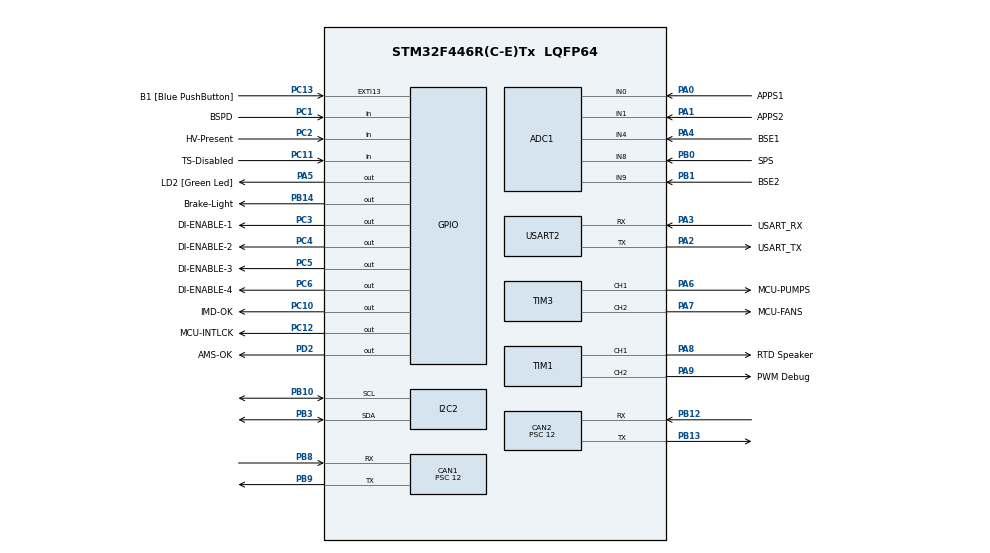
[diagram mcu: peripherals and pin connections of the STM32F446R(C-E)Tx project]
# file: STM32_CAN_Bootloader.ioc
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ADC1.Channel-2\#ChannelRegularConversion=ADC_CHANNEL_1
ADC1.Channel-3\#ChannelRegularConversion=ADC_CHANNEL_4
ADC1.Channel-4\#ChannelRegularConversion=ADC_CHANNEL_9
ADC1.Channel-5\#ChannelRegularConversion=ADC_CHANNEL_8
ADC1.Channel-8\#ChannelRegularConversion=ADC_CHANNEL_VREFINT
ADC1.DMAContinuousRequests=DISABLE
ADC1.EOCSelection=ADC_EOC_SEQ_CONV
ADC1.ExternalTrigConv=ADC_SOFTWARE_START
ADC1.NbrOfConversion=6
ADC1.NbrOfConversionFlag=1
ADC1.Rank-2\#ChannelRegularConversion=2
ADC1.Rank-3\#ChannelRegularConversion=3
ADC1.Rank-4\#ChannelRegularConversion=4
ADC1.Rank-5\#ChannelRegularConversion=5
ADC1.Rank-8\#ChannelRegularConversion=6
ADC1.SamplingTime-1\#ChannelRegularConversion=ADC_SAMPLETIME_56CYCLES
ADC1.SamplingTime-2\#ChannelRegularConversion=ADC_SAMPLETIME_56CYCLES
ADC1.SamplingTime-3\#ChannelRegularConversion=ADC_SAMPLETIME_56CYCLES
ADC1.SamplingTime-4\#ChannelRegularConversion=ADC_SAMPLETIME_56CYCLES
ADC1.SamplingTime-5\#ChannelRegularConversion=ADC_SAMPLETIME_56CYCLES
ADC1.SamplingTime-8\#ChannelRegularConversion=ADC_SAMPLETIME_480CYCLES
ADC1.master=1
CAN1.ABOM=ENABLE
CAN1.AWUM=ENABLE
CAN1.BS1=CAN_BS1_10TQ
CAN1.BS2=CAN_BS2_3TQ
CAN1.CalculateBaudRate=250000
CAN1.CalculateTimeBit=4000
CAN1.CalculateTimeQuantum=285.7142857142857
CAN1.NART=ENABLE
CAN1.Prescaler=12
CAN1.TXFP=ENABLE
CAN2.ABOM=ENABLE
CAN2.AWUM=ENABLE
CAN2.BS1=CAN_BS1_10TQ
CAN2.BS2=CAN_BS2_3TQ
CAN2.CalculateBaudRate=250000
CAN2.CalculateTimeBit=4000
CAN2.CalculateTimeQuantum=285.7142857142857
CAN2.NART=ENABLE
CAN2.Prescaler=12
Dma.ADC1.0.Direction=DMA_PERIPH_TO_MEMORY
Dma.ADC1.0.FIFOMode=DMA_FIFOMODE_DISABLE
Dma.ADC1.0.Instance=DMA2_Stream0
Dma.ADC1.0.MemDataAlignment=DMA_MDATAALIGN_HALFWORD
Dma.ADC1.0.MemInc=DMA_MINC_ENABLE
Dma.ADC1.0.Mode=DMA_CIRCULAR
Dma.ADC1.0.PeriphDataAlignment=DMA_PDATAALIGN_HALFWORD
Dma.ADC1.0.PeriphInc=DMA_PINC_DISABLE
Dma.ADC1.0.Priority=DMA_PRIORITY_LOW
Dma.Request0=ADC1
Dma.Request1=USART2_RX
Dma.USART2_RX.1.Direction=DMA_PERIPH_TO_MEMORY
Dma.USART2_RX.1.FIFOMode=DMA_FIFOMODE_DISABLE
Dma.USART2_RX.1.Instance=DMA1_Stream5
Dma.USART2_RX.1.MemDataAlignment=DMA_MDATAALIGN_BYTE
Dma.USART2_RX.1.MemInc=DMA_MINC_ENABLE
Dma.USART2_RX.1.Mode=DMA_NORMAL
Dma.USART2_RX.1.PeriphDataAlignment=DMA_PDATAALIGN_BYTE
Dma.USART2_RX.1.PeriphInc=DMA_PINC_DISABLE
Dma.USART2_RX.1.Priority=DMA_PRIORITY_LOW
Mcu.Family=STM32F4
Mcu.Name=STM32F446R(C-E)Tx
Mcu.Package=LQFP64
NVIC.CAN1_RX0_IRQn=true\:0\:0\:false\:false\:true\:true\:true\:true
NVIC.CAN1_RX1_IRQn=true\:0\:0\:false\:false\:true\:true\:true\:true
NVIC.CAN1_TX_IRQn=true\:0\:0\:false\:false\:true\:true\:true\:true
NVIC.CAN2_RX0_IRQn=true\:0\:0\:false\:false\:true\:true\:true\:true
NVIC.CAN2_TX_IRQn=true\:0\:0\:false\:false\:true\:true\:true\:true
NVIC.DMA1_Stream5_IRQn=true\:0\:0\:false\:false\:true\:false\:true\:true
NVIC.DMA2_Stream0_IRQn=true\:0\:0\:false\:false\:true\:false\:true\:true
NVIC.PriorityGroup=NVIC_PRIORITYGROUP_4
NVIC.TIM5_IRQn=true\:15\:0\:false\:false\:true\:false\:true\:true
NVIC.TimeBase=TIM5_IRQn
NVIC.TimeBaseIP=TIM5
PA0-WKUP.GPIO_Label=APPS1
PA0-WKUP.GPIO_Mode=GPIO_MODE_ANALOG
PA0-WKUP.GPIO_PuPd=GPIO_NOPULL
PA0-WKUP.Signal=ADCx_IN0
PA1.GPIO_Label=APPS2
PA1.GPIO_Mode=GPIO_MODE_ANALOG
PA1.GPIO_PuPd=GPIO_NOPULL
PA1.Signal=ADCx_IN1
PA13.GPIO_Label=TMS
PA13.Mode=Serial_Wire
PA13.Signal=SYS_JTMS-SWDIO
PA14.GPIO_Label=TCK
PA14.Mode=Serial_Wire
PA14.Signal=SYS_JTCK-SWCLK
PA2.GPIO_Label=USART_TX
PA2.Mode=Asynchronous
PA2.Signal=USART2_TX
PA3.GPIO_Label=USART_RX
PA3.Mode=Asynchronous
PA3.Signal=USART2_RX
PA4.GPIO_Label=BSE1
PA4.Signal=ADCx_IN4
PA5.GPIO_Label=LD2 [Green Led]
PA5.Signal=GPIO_Output
PA6.GPIO_Label=MCU-PUMPS
PA6.Signal=S_TIM3_CH1
PA7.GPIO_Label=MCU-FANS
PA7.Signal=S_TIM3_CH2
PA8.GPIO_Label=RTD Speaker
PA8.Signal=S_TIM1_CH1
PA9.GPIO_Label=PWM Debug
PA9.Signal=S_TIM1_CH2
PB0.GPIO_Label=SPS
PB0.GPIO_Mode=GPIO_MODE_ANALOG
PB0.GPIO_PuPd=GPIO_NOPULL
PB0.Signal=ADCx_IN8
PB1.GPIO_Label=BSE2
PB1.GPIO_Mode=GPIO_MODE_ANALOG
PB1.GPIO_PuPd=GPIO_NOPULL
PB1.Signal=ADCx_IN9
PB10.Mode=I2C
PB10.Signal=I2C2_SCL
PB12.Mode=CAN_Activate
PB12.Signal=CAN2_RX
PB13.Mode=CAN_Activate
PB13.Signal=CAN2_TX
PB14.GPIO_Label=Brake-Light
PB14.Signal=GPIO_Output
PB3.Mode=I2C
PB3.Signal=I2C2_SDA
PB7.Signal=USART1_RX
PB8.Mode=CAN_Activate
PB8.Signal=CAN1_RX
PB9.Mode=CAN_Activate
PB9.Signal=CAN1_TX
PC1.GPIO_Label=BSPD
PC1.Signal=GPIO_Input
PC10.GPIO_Label=IMD-OK
PC10.Signal=GPIO_Output
PC11.GPIO_Label=TS-Disabled
PC11.Signal=GPIO_Input
PC12.GPIO_Label=MCU-INTLCK
PC12.Signal=GPIO_Output
PC13.GPIO_Label=B1 [Blue PushButton]
PC13.GPIO_ModeDefaultEXTI=GPIO_MODE_IT_FALLING
PC13.Signal=GPXTI13
PC14-OSC32_IN.Mode=LSE-External-Oscillator
PC14-OSC32_IN.Signal=RCC_OSC32_IN
PC15-OSC32_OUT.Mode=LSE-External-Oscillator
PC15-OSC32_OUT.Signal=RCC_OSC32_OUT
PC2.GPIO_Label=HV-Present
PC2.Signal=GPIO_Input
PC3.GPIO_Label=DI-ENABLE-1
PC3.GPIO_ModeDefaultOutputPP=GPIO_MODE_OUTPUT_OD
PC3.GPIO_PuPd=GPIO_NOPULL
PC3.PinState=GPIO_PIN_SET
PC3.Signal=GPIO_Output
PC4.GPIO_Label=DI-ENABLE-2
PC4.GPIO_ModeDefaultOutputPP=GPIO_MODE_OUTPUT_OD
PC4.GPIO_PuPd=GPIO_NOPULL
PC4.PinState=GPIO_PIN_SET
PC4.Signal=GPIO_Output
PC5.GPIO_Label=DI-ENABLE-3
PC5.GPIO_ModeDefaultOutputPP=GPIO_MODE_OUTPUT_OD
PC5.GPIO_PuPd=GPIO_NOPULL
PC5.PinState=GPIO_PIN_SET
PC5.Signal=GPIO_Output
PC6.GPIO_Label=DI-ENABLE-4
PC6.GPIO_ModeDefaultOutputPP=GPIO_MODE_OUTPUT_OD
PC6.GPIO_PuPd=GPIO_NOPULL
PC6.PinState=GPIO_PIN_SET
PC6.Signal=GPIO_Output
PD2.GPIO_Label=AMS-OK
PD2.Signal=GPIO_Output
PH0-OSC_IN.Mode=HSE-External-Oscillator
PH0-OSC_IN.Signal=RCC_OSC_IN
PH1-OSC_OUT.Mode=HSE-External-Oscillator
PH1-OSC_OUT.Signal=RCC_OSC_OUT
ProjectManager.HeapSize=0x200
ProjectManager.StackSize=0x400
ProjectManager.TargetToolchain=STM32CubeIDE
RCC.48MHZClocksFreq_Value=84000000
RCC.AHBFreq_Value=84000000
RCC.APB1CLKDivider=RCC_HCLK_DIV2
RCC.APB1Freq_Value=42000000
RCC.APB1TimFreq_Value=84000000
RCC.APB2Freq_Value=84000000
RCC.APB2TimFreq_Value=84000000
RCC.CortexFreq_Value=84000000
RCC.FLatency-AdvancedSettings=FLASH_LATENCY_2
RCC.HCLKFreq_Value=84000000
RCC.HSE_VALUE=8000000
RCC.HSI_VALUE=16000000
RCC.PLLN=336
RCC.PLLP=RCC_PLLP_DIV4
RCC.SYSCLKFreq_VALUE=84000000
RCC.SYSCLKSource=RCC_SYSCLKSOURCE_PLLCLK
RCC.USBFreq_Value=168000000
RCC.VCOOutputFreq_Value=336000000
SH.ADCx_IN0.0=ADC1_IN0,IN0
SH.ADCx_IN1.0=ADC1_IN1,IN1
SH.ADCx_IN4.0=ADC1_IN4,IN4
SH.ADCx_IN8.0=ADC1_IN8,IN8
SH.ADCx_IN9.0=ADC1_IN9,IN9
SH.S_TIM1_CH1.0=TIM1_CH1,PWM Generation1 CH1
SH.S_TIM1_CH2.0=TIM1_CH2,PWM Generation2 CH2
SH.S_TIM3_CH1.0=TIM3_CH1,PWM Generation1 CH1
SH.S_TIM3_CH2.0=TIM3_CH2,PWM Generation2 CH2
TIM1.Channel-PWM\ Generation1\ CH1=TIM_CHANNEL_1
TIM1.Channel-PWM\ Generation2\ CH2=TIM_CHANNEL_2
TIM3.Channel-PWM\ Generation1\ CH1=TIM_CHANNEL_1
TIM3.Channel-PWM\ Generation2\ CH2=TIM_CHANNEL_2
USART2.VirtualMode=VM_ASYNC
VP_ADC1_Vref_Input.Mode=IN-Vrefint
VP_SYS_VS_tim5.Mode=TIM5
VP_TIM1_VS_ClockSourceINT.Mode=Internal
VP_TIM3_VS_ClockSourceINT.Mode=Internal
board=NUCLEO-F446RE

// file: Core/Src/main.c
/* USER CODE BEGIN Header */
/**
  ******************************************************************************
  * @file           : main.c
  * @brief          : Main program body
  ******************************************************************************
  * @attention
  *
  * Copyright (c) 2026 STMicroelectronics.
  * All rights reserved.
  *
  * This software is licensed under terms that can be found in the LICENSE file
  * in the root directory of this software component.
  * If no LICENSE file comes with this software, it is provided AS-IS.
  *
  ******************************************************************************
  */
/* USER CODE END Header */
#include "main.h"

/* USER CODE BEGIN Includes */
#include "bootloader.h"
/* USER CODE END Includes */

CAN_HandleTypeDef hcan1;
CAN_HandleTypeDef hcan2;

I2C_HandleTypeDef hi2c2;

void SystemClock_Config(void);

int main(void)
{

  /* MCU Configuration--------------------------------------------------------*/

  /* Reset of all peripherals, Initializes the Flash interface and the Systick. */
  HAL_Init();

  /* Configure the system clock */
  SystemClock_Config();

  /* Initialize all configured peripherals */
  MX_GPIO_Init();
  MX_DMA_Init();
  MX_ADC1_Init();
  MX_CAN1_Init();
  MX_CAN2_Init();
  MX_TIM1_Init();
  MX_TIM3_Init();
  MX_USART2_UART_Init();
  MX_I2C2_Init();
  /* USER CODE BEGIN 2 */
  BL_Run(&hcan1);   /* never returns — either flashes then jumps, or jumps directly */
  /* USER CODE END 2 */

  /* Infinite loop */
  while (1)
  {

  }
}

void SystemClock_Config(void)
{
  LL_FLASH_SetLatency(LL_FLASH_LATENCY_2);
  while(LL_FLASH_GetLatency()!= LL_FLASH_LATENCY_2)
  {
  }
  LL_PWR_SetRegulVoltageScaling(LL_PWR_REGU_VOLTAGE_SCALE3);
  LL_PWR_DisableOverDriveMode();
  LL_RCC_HSI_SetCalibTrimming(16);
  LL_RCC_HSI_Enable();

   /* Wait till HSI is ready */
  while(LL_RCC_HSI_IsReady() != 1)
  {

  }
  LL_RCC_PLL_ConfigDomain_SYS(LL_RCC_PLLSOURCE_HSI, LL_RCC_PLLM_DIV_16, 336, LL_RCC_PLLP_DIV_4);
  LL_RCC_PLL_Enable();

   /* Wait till PLL is ready */
  while(LL_RCC_PLL_IsReady() != 1)
  {

  }
  while (LL_PWR_IsActiveFlag_VOS() == 0)
  {
  }
  LL_RCC_SetAHBPrescaler(LL_RCC_SYSCLK_DIV_1);
  LL_RCC_SetAPB1Prescaler(LL_RCC_APB1_DIV_2);
  LL_RCC_SetAPB2Prescaler(LL_RCC_APB2_DIV_1);
  LL_RCC_SetSysClkSource(LL_RCC_SYS_CLKSOURCE_PLL);

   /* Wait till System clock is ready */
  while(LL_RCC_GetSysClkSource() != LL_RCC_SYS_CLKSOURCE_STATUS_PLL)
  {

  }
  LL_SetSystemCoreClock(84000000);

   /* Update the time base */
  if (HAL_InitTick (TICK_INT_PRIORITY) != HAL_OK)
  {
    Error_Handler();
  }
  LL_RCC_SetTIMPrescaler(LL_RCC_TIM_PRESCALER_TWICE);
}

void MX_ADC1_Init(void)
{

  LL_ADC_InitTypeDef ADC_InitStruct = {0};
  LL_ADC_REG_InitTypeDef ADC_REG_InitStruct = {0};
  LL_ADC_CommonInitTypeDef ADC_CommonInitStruct = {0};

  LL_GPIO_InitTypeDef GPIO_InitStruct = {0};

  /* Peripheral clock enable */
  LL_APB2_GRP1_EnableClock(LL_APB2_GRP1_PERIPH_ADC1);

  LL_AHB1_GRP1_EnableClock(LL_AHB1_GRP1_PERIPH_GPIOA);
  LL_AHB1_GRP1_EnableClock(LL_AHB1_GRP1_PERIPH_GPIOB);
  /**ADC1 GPIO Configuration
  PA0-WKUP   ------> ADC1_IN0
  PA1   ------> ADC1_IN1
  PA4   ------> ADC1_IN4
  PB0   ------> ADC1_IN8
  PB1   ------> ADC1_IN9
  */
  GPIO_InitStruct.Pin = APPS1_Pin|APPS2_Pin|BSE1_Pin;
  GPIO_InitStruct.Mode = LL_GPIO_MODE_ANALOG;
  GPIO_InitStruct.Pull = LL_GPIO_PULL_NO;
  LL_GPIO_Init(GPIOA, &GPIO_InitStruct);

  GPIO_InitStruct.Pin = SPS_Pin|BSE2_Pin;
  GPIO_InitStruct.Mode = LL_GPIO_MODE_ANALOG;
  GPIO_InitStruct.Pull = LL_GPIO_PULL_NO;
  LL_GPIO_Init(GPIOB, &GPIO_InitStruct);

  /* ADC1 DMA Init */

  /* ADC1 Init */
  LL_DMA_SetChannelSelection(DMA2, LL_DMA_STREAM_0, LL_DMA_CHANNEL_0);

  LL_DMA_SetDataTransferDirection(DMA2, LL_DMA_STREAM_0, LL_DMA_DIRECTION_PERIPH_TO_MEMORY);

  LL_DMA_SetStreamPriorityLevel(DMA2, LL_DMA_STREAM_0, LL_DMA_PRIORITY_LOW);

  LL_DMA_SetMode(DMA2, LL_DMA_STREAM_0, LL_DMA_MODE_CIRCULAR);

  LL_DMA_SetPeriphIncMode(DMA2, LL_DMA_STREAM_0, LL_DMA_PERIPH_NOINCREMENT);

  LL_DMA_SetMemoryIncMode(DMA2, LL_DMA_STREAM_0, LL_DMA_MEMORY_INCREMENT);

  LL_DMA_SetPeriphSize(DMA2, LL_DMA_STREAM_0, LL_DMA_PDATAALIGN_HALFWORD);

  LL_DMA_SetMemorySize(DMA2, LL_DMA_STREAM_0, LL_DMA_MDATAALIGN_HALFWORD);

  LL_DMA_DisableFifoMode(DMA2, LL_DMA_STREAM_0);

  /** Common config
  */
  ADC_InitStruct.Resolution = LL_ADC_RESOLUTION_12B;
  ADC_InitStruct.DataAlignment = LL_ADC_DATA_ALIGN_RIGHT;
  ADC_InitStruct.SequencersScanMode = LL_ADC_SEQ_SCAN_ENABLE;
  LL_ADC_Init(ADC1, &ADC_InitStruct);
  ADC_REG_InitStruct.TriggerSource = LL_ADC_REG_TRIG_SOFTWARE;
  ADC_REG_InitStruct.SequencerLength = LL_ADC_REG_SEQ_SCAN_ENABLE_6RANKS;
  ADC_REG_InitStruct.SequencerDiscont = LL_ADC_REG_SEQ_DISCONT_DISABLE;
  ADC_REG_InitStruct.ContinuousMode = LL_ADC_REG_CONV_SINGLE;
  ADC_REG_InitStruct.DMATransfer = LL_ADC_REG_DMA_TRANSFER_LIMITED;
  LL_ADC_REG_Init(ADC1, &ADC_REG_InitStruct);
  LL_ADC_REG_SetFlagEndOfConversion(ADC1, LL_ADC_REG_FLAG_EOC_SEQUENCE_CONV);
  ADC_CommonInitStruct.CommonClock = LL_ADC_CLOCK_SYNC_PCLK_DIV4;
  ADC_CommonInitStruct.Multimode = LL_ADC_MULTI_INDEPENDENT;
  LL_ADC_CommonInit(__LL_ADC_COMMON_INSTANCE(ADC1), &ADC_CommonInitStruct);

  /** Configure Regular Channel
  */
  LL_ADC_REG_SetSequencerRanks(ADC1, LL_ADC_REG_RANK_2, LL_ADC_CHANNEL_1);
  LL_ADC_SetChannelSamplingTime(ADC1, LL_ADC_CHANNEL_1, LL_ADC_SAMPLINGTIME_56CYCLES);

  /** Configure Regular Channel
  */
  LL_ADC_REG_SetSequencerRanks(ADC1, LL_ADC_REG_RANK_3, LL_ADC_CHANNEL_4);
  LL_ADC_SetChannelSamplingTime(ADC1, LL_ADC_CHANNEL_4, LL_ADC_SAMPLINGTIME_56CYCLES);

  /** Configure Regular Channel
  */
  LL_ADC_REG_SetSequencerRanks(ADC1, LL_ADC_REG_RANK_4, LL_ADC_CHANNEL_9);
  LL_ADC_SetChannelSamplingTime(ADC1, LL_ADC_CHANNEL_9, LL_ADC_SAMPLINGTIME_56CYCLES);

  /** Configure Regular Channel
  */
  LL_ADC_REG_SetSequencerRanks(ADC1, LL_ADC_REG_RANK_5, LL_ADC_CHANNEL_8);
  LL_ADC_SetChannelSamplingTime(ADC1, LL_ADC_CHANNEL_8, LL_ADC_SAMPLINGTIME_56CYCLES);

  /** Configure Regular Channel
  */
  LL_ADC_REG_SetSequencerRanks(ADC1, LL_ADC_REG_RANK_1, LL_ADC_CHANNEL_0);
  LL_ADC_SetChannelSamplingTime(ADC1, LL_ADC_CHANNEL_0, LL_ADC_SAMPLINGTIME_56CYCLES);

  /** Configure Regular Channel
  */
  LL_ADC_REG_SetSequencerRanks(ADC1, LL_ADC_REG_RANK_6, LL_ADC_CHANNEL_VREFINT);
  LL_ADC_SetChannelSamplingTime(ADC1, LL_ADC_CHANNEL_VREFINT, LL_ADC_SAMPLINGTIME_480CYCLES);
  LL_ADC_SetCommonPathInternalCh(__LL_ADC_COMMON_INSTANCE(ADC1), LL_ADC_PATH_INTERNAL_VREFINT);

}

void MX_CAN1_Init(void)
{

  hcan1.Instance = CAN1;
  hcan1.Init.Prescaler = 12;
  hcan1.Init.Mode = CAN_MODE_NORMAL;
  hcan1.Init.SyncJumpWidth = CAN_SJW_1TQ;
  hcan1.Init.TimeSeg1 = CAN_BS1_10TQ;
  hcan1.Init.TimeSeg2 = CAN_BS2_3TQ;
  hcan1.Init.TimeTriggeredMode = DISABLE;
  hcan1.Init.AutoBusOff = ENABLE;
  hcan1.Init.AutoWakeUp = ENABLE;
  hcan1.Init.AutoRetransmission = ENABLE;
  hcan1.Init.ReceiveFifoLocked = DISABLE;
  hcan1.Init.TransmitFifoPriority = ENABLE;
  if (HAL_CAN_Init(&hcan1) != HAL_OK)
  {
    Error_Handler();
  }

}

void MX_CAN2_Init(void)
{

  hcan2.Instance = CAN2;
  hcan2.Init.Prescaler = 12;
  hcan2.Init.Mode = CAN_MODE_NORMAL;
  hcan2.Init.SyncJumpWidth = CAN_SJW_1TQ;
  hcan2.Init.TimeSeg1 = CAN_BS1_10TQ;
  hcan2.Init.TimeSeg2 = CAN_BS2_3TQ;
  hcan2.Init.TimeTriggeredMode = DISABLE;
  hcan2.Init.AutoBusOff = ENABLE;
  hcan2.Init.AutoWakeUp = ENABLE;
  hcan2.Init.AutoRetransmission = ENABLE;
  hcan2.Init.ReceiveFifoLocked = DISABLE;
  hcan2.Init.TransmitFifoPriority = DISABLE;
  if (HAL_CAN_Init(&hcan2) != HAL_OK)
  {
    Error_Handler();
  }

}

void MX_I2C2_Init(void)
{

  hi2c2.Instance = I2C2;
  hi2c2.Init.ClockSpeed = 100000;
  hi2c2.Init.DutyCycle = I2C_DUTYCYCLE_2;
  hi2c2.Init.OwnAddress1 = 0;
  hi2c2.Init.AddressingMode = I2C_ADDRESSINGMODE_7BIT;
  hi2c2.Init.DualAddressMode = I2C_DUALADDRESS_DISABLE;
  hi2c2.Init.OwnAddress2 = 0;
  hi2c2.Init.GeneralCallMode = I2C_GENERALCALL_DISABLE;
  hi2c2.Init.NoStretchMode = I2C_NOSTRETCH_DISABLE;
  if (HAL_I2C_Init(&hi2c2) != HAL_OK)
  {
    Error_Handler();
  }

}

void MX_TIM1_Init(void)
{

  LL_TIM_InitTypeDef TIM_InitStruct = {0};
  LL_TIM_OC_InitTypeDef TIM_OC_InitStruct = {0};
  LL_TIM_BDTR_InitTypeDef TIM_BDTRInitStruct = {0};

  LL_GPIO_InitTypeDef GPIO_InitStruct = {0};

  /* Peripheral clock enable */
  LL_APB2_GRP1_EnableClock(LL_APB2_GRP1_PERIPH_TIM1);

  TIM_InitStruct.Prescaler = 0;
  TIM_InitStruct.CounterMode = LL_TIM_COUNTERMODE_UP;
  TIM_InitStruct.Autoreload = 65535;
  TIM_InitStruct.ClockDivision = LL_TIM_CLOCKDIVISION_DIV1;
  TIM_InitStruct.RepetitionCounter = 0;
  LL_TIM_Init(TIM1, &TIM_InitStruct);
  LL_TIM_DisableARRPreload(TIM1);
  LL_TIM_SetClockSource(TIM1, LL_TIM_CLOCKSOURCE_INTERNAL);
  LL_TIM_OC_EnablePreload(TIM1, LL_TIM_CHANNEL_CH1);
  TIM_OC_InitStruct.OCMode = LL_TIM_OCMODE_PWM1;
  TIM_OC_InitStruct.OCState = LL_TIM_OCSTATE_DISABLE;
  TIM_OC_InitStruct.OCNState = LL_TIM_OCSTATE_DISABLE;
  TIM_OC_InitStruct.CompareValue = 0;
  TIM_OC_InitStruct.OCPolarity = LL_TIM_OCPOLARITY_HIGH;
  TIM_OC_InitStruct.OCNPolarity = LL_TIM_OCPOLARITY_HIGH;
  TIM_OC_InitStruct.OCIdleState = LL_TIM_OCIDLESTATE_LOW;
  TIM_OC_InitStruct.OCNIdleState = LL_TIM_OCIDLESTATE_LOW;
  LL_TIM_OC_Init(TIM1, LL_TIM_CHANNEL_CH1, &TIM_OC_InitStruct);
  LL_TIM_OC_DisableFast(TIM1, LL_TIM_CHANNEL_CH1);
  LL_TIM_OC_EnablePreload(TIM1, LL_TIM_CHANNEL_CH2);
  LL_TIM_OC_Init(TIM1, LL_TIM_CHANNEL_CH2, &TIM_OC_InitStruct);
  LL_TIM_OC_DisableFast(TIM1, LL_TIM_CHANNEL_CH2);
  LL_TIM_SetTriggerOutput(TIM1, LL_TIM_TRGO_RESET);
  LL_TIM_DisableMasterSlaveMode(TIM1);
  TIM_BDTRInitStruct.OSSRState = LL_TIM_OSSR_DISABLE;
  TIM_BDTRInitStruct.OSSIState = LL_TIM_OSSI_DISABLE;
  TIM_BDTRInitStruct.LockLevel = LL_TIM_LOCKLEVEL_OFF;
  TIM_BDTRInitStruct.DeadTime = 0;
  TIM_BDTRInitStruct.BreakState = LL_TIM_BREAK_DISABLE;
  TIM_BDTRInitStruct.BreakPolarity = LL_TIM_BREAK_POLARITY_HIGH;
  TIM_BDTRInitStruct.AutomaticOutput = LL_TIM_AUTOMATICOUTPUT_DISABLE;
  LL_TIM_BDTR_Init(TIM1, &TIM_BDTRInitStruct);
  LL_AHB1_GRP1_EnableClock(LL_AHB1_GRP1_PERIPH_GPIOA);
  /**TIM1 GPIO Configuration
  PA8   ------> TIM1_CH1
  PA9   ------> TIM1_CH2
  */
  GPIO_InitStruct.Pin = RTD_Speaker_Pin|PWM_Debug_Pin;
  GPIO_InitStruct.Mode = LL_GPIO_MODE_ALTERNATE;
  GPIO_InitStruct.Speed = LL_GPIO_SPEED_FREQ_LOW;
  GPIO_InitStruct.OutputType = LL_GPIO_OUTPUT_PUSHPULL;
  GPIO_InitStruct.Pull = LL_GPIO_PULL_NO;
  GPIO_InitStruct.Alternate = LL_GPIO_AF_1;
  LL_GPIO_Init(GPIOA, &GPIO_InitStruct);

}

void MX_TIM3_Init(void)
{

  LL_TIM_InitTypeDef TIM_InitStruct = {0};
  LL_TIM_OC_InitTypeDef TIM_OC_InitStruct = {0};

  LL_GPIO_InitTypeDef GPIO_InitStruct = {0};

  /* Peripheral clock enable */
  LL_APB1_GRP1_EnableClock(LL_APB1_GRP1_PERIPH_TIM3);

  TIM_InitStruct.Prescaler = 0;
  TIM_InitStruct.CounterMode = LL_TIM_COUNTERMODE_UP;
  TIM_InitStruct.Autoreload = 65535;
  TIM_InitStruct.ClockDivision = LL_TIM_CLOCKDIVISION_DIV1;
  LL_TIM_Init(TIM3, &TIM_InitStruct);
  LL_TIM_DisableARRPreload(TIM3);
  LL_TIM_SetClockSource(TIM3, LL_TIM_CLOCKSOURCE_INTERNAL);
  LL_TIM_OC_EnablePreload(TIM3, LL_TIM_CHANNEL_CH1);
  TIM_OC_InitStruct.OCMode = LL_TIM_OCMODE_PWM1;
  TIM_OC_InitStruct.OCState = LL_TIM_OCSTATE_DISABLE;
  TIM_OC_InitStruct.OCNState = LL_TIM_OCSTATE_DISABLE;
  TIM_OC_InitStruct.CompareValue = 0;
  TIM_OC_InitStruct.OCPolarity = LL_TIM_OCPOLARITY_HIGH;
  LL_TIM_OC_Init(TIM3, LL_TIM_CHANNEL_CH1, &TIM_OC_InitStruct);
  LL_TIM_OC_DisableFast(TIM3, LL_TIM_CHANNEL_CH1);
  LL_TIM_OC_EnablePreload(TIM3, LL_TIM_CHANNEL_CH2);
  LL_TIM_OC_Init(TIM3, LL_TIM_CHANNEL_CH2, &TIM_OC_InitStruct);
  LL_TIM_OC_DisableFast(TIM3, LL_TIM_CHANNEL_CH2);
  LL_TIM_SetTriggerOutput(TIM3, LL_TIM_TRGO_RESET);
  LL_TIM_DisableMasterSlaveMode(TIM3);
  LL_AHB1_GRP1_EnableClock(LL_AHB1_GRP1_PERIPH_GPIOA);
  /**TIM3 GPIO Configuration
  PA6   ------> TIM3_CH1
  PA7   ------> TIM3_CH2
  */
  GPIO_InitStruct.Pin = MCU_PUMPS_Pin|MCU_FANS_Pin;
  GPIO_InitStruct.Mode = LL_GPIO_MODE_ALTERNATE;
  GPIO_InitStruct.Speed = LL_GPIO_SPEED_FREQ_LOW;
  GPIO_InitStruct.OutputType = LL_GPIO_OUTPUT_PUSHPULL;
  GPIO_InitStruct.Pull = LL_GPIO_PULL_NO;
  GPIO_InitStruct.Alternate = LL_GPIO_AF_2;
  LL_GPIO_Init(GPIOA, &GPIO_InitStruct);

}

void MX_USART2_UART_Init(void)
{

  LL_USART_InitTypeDef USART_InitStruct = {0};

  LL_GPIO_InitTypeDef GPIO_InitStruct = {0};

  /* Peripheral clock enable */
  LL_APB1_GRP1_EnableClock(LL_APB1_GRP1_PERIPH_USART2);

  LL_AHB1_GRP1_EnableClock(LL_AHB1_GRP1_PERIPH_GPIOA);
  /**USART2 GPIO Configuration
  PA2   ------> USART2_TX
  PA3   ------> USART2_RX
  */
  GPIO_InitStruct.Pin = USART_TX_Pin|USART_RX_Pin;
  GPIO_InitStruct.Mode = LL_GPIO_MODE_ALTERNATE;
  GPIO_InitStruct.Speed = LL_GPIO_SPEED_FREQ_VERY_HIGH;
  GPIO_InitStruct.OutputType = LL_GPIO_OUTPUT_PUSHPULL;
  GPIO_InitStruct.Pull = LL_GPIO_PULL_NO;
  GPIO_InitStruct.Alternate = LL_GPIO_AF_7;
  LL_GPIO_Init(GPIOA, &GPIO_InitStruct);

  /* USART2 DMA Init */

  /* USART2_RX Init */
  LL_DMA_SetChannelSelection(DMA1, LL_DMA_STREAM_5, LL_DMA_CHANNEL_4);

  LL_DMA_SetDataTransferDirection(DMA1, LL_DMA_STREAM_5, LL_DMA_DIRECTION_PERIPH_TO_MEMORY);

  LL_DMA_SetStreamPriorityLevel(DMA1, LL_DMA_STREAM_5, LL_DMA_PRIORITY_LOW);

  LL_DMA_SetMode(DMA1, LL_DMA_STREAM_5, LL_DMA_MODE_NORMAL);

  LL_DMA_SetPeriphIncMode(DMA1, LL_DMA_STREAM_5, LL_DMA_PERIPH_NOINCREMENT);

  LL_DMA_SetMemoryIncMode(DMA1, LL_DMA_STREAM_5, LL_DMA_MEMORY_INCREMENT);

  LL_DMA_SetPeriphSize(DMA1, LL_DMA_STREAM_5, LL_DMA_PDATAALIGN_BYTE);

  LL_DMA_SetMemorySize(DMA1, LL_DMA_STREAM_5, LL_DMA_MDATAALIGN_BYTE);

  LL_DMA_DisableFifoMode(DMA1, LL_DMA_STREAM_5);

  USART_InitStruct.BaudRate = 115200;
  USART_InitStruct.DataWidth = LL_USART_DATAWIDTH_8B;
  USART_InitStruct.StopBits = LL_USART_STOPBITS_1;
  USART_InitStruct.Parity = LL_USART_PARITY_NONE;
  USART_InitStruct.TransferDirection = LL_USART_DIRECTION_TX_RX;
  USART_InitStruct.HardwareFlowControl = LL_USART_HWCONTROL_NONE;
  USART_InitStruct.OverSampling = LL_USART_OVERSAMPLING_16;
  LL_USART_Init(USART2, &USART_InitStruct);
  LL_USART_ConfigAsyncMode(USART2);
  LL_USART_Enable(USART2);

}

void MX_DMA_Init(void)
{

  /* Init with LL driver */
  /* DMA controller clock enable */
  LL_AHB1_GRP1_EnableClock(LL_AHB1_GRP1_PERIPH_DMA2);
  LL_AHB1_GRP1_EnableClock(LL_AHB1_GRP1_PERIPH_DMA1);

  /* DMA interrupt init */
  /* DMA1_Stream5_IRQn interrupt configuration */
  NVIC_SetPriority(DMA1_Stream5_IRQn, NVIC_EncodePriority(NVIC_GetPriorityGrouping(),0, 0));
  NVIC_EnableIRQ(DMA1_Stream5_IRQn);
  /* DMA2_Stream0_IRQn interrupt configuration */
  NVIC_SetPriority(DMA2_Stream0_IRQn, NVIC_EncodePriority(NVIC_GetPriorityGrouping(),0, 0));
  NVIC_EnableIRQ(DMA2_Stream0_IRQn);

}

void MX_GPIO_Init(void)
{
  LL_EXTI_InitTypeDef EXTI_InitStruct = {0};
  LL_GPIO_InitTypeDef GPIO_InitStruct = {0};

  /* GPIO Ports Clock Enable */
  LL_AHB1_GRP1_EnableClock(LL_AHB1_GRP1_PERIPH_GPIOC);
  LL_AHB1_GRP1_EnableClock(LL_AHB1_GRP1_PERIPH_GPIOH);
  LL_AHB1_GRP1_EnableClock(LL_AHB1_GRP1_PERIPH_GPIOA);
  LL_AHB1_GRP1_EnableClock(LL_AHB1_GRP1_PERIPH_GPIOB);
  LL_AHB1_GRP1_EnableClock(LL_AHB1_GRP1_PERIPH_GPIOD);

  /**/
  LL_GPIO_SetOutputPin(GPIOC, DI_ENABLE_1_Pin|DI_ENABLE_2_Pin|DI_ENABLE_3_Pin|DI_ENABLE_4_Pin);

  /**/
  LL_GPIO_ResetOutputPin(LD2_GPIO_Port, LD2_Pin);

  /**/
  LL_GPIO_ResetOutputPin(Brake_Light_GPIO_Port, Brake_Light_Pin);

  /**/
  LL_GPIO_ResetOutputPin(GPIOC, IMD_OK_Pin|MCU_INTLCK_Pin);

  /**/
  LL_GPIO_ResetOutputPin(AMS_OK_GPIO_Port, AMS_OK_Pin);

  /**/
  LL_SYSCFG_SetEXTISource(LL_SYSCFG_EXTI_PORTC, LL_SYSCFG_EXTI_LINE13);

  /**/
  EXTI_InitStruct.Line_0_31 = LL_EXTI_LINE_13;
  EXTI_InitStruct.LineCommand = ENABLE;
  EXTI_InitStruct.Mode = LL_EXTI_MODE_IT;
  EXTI_InitStruct.Trigger = LL_EXTI_TRIGGER_FALLING;
  LL_EXTI_Init(&EXTI_InitStruct);

  /**/
  LL_GPIO_SetPinPull(B1_GPIO_Port, B1_Pin, LL_GPIO_PULL_NO);

  /**/
  LL_GPIO_SetPinMode(B1_GPIO_Port, B1_Pin, LL_GPIO_MODE_INPUT);

  /**/
  GPIO_InitStruct.Pin = BSPD_Pin|HV_Present_Pin|TS_Disabled_Pin;
  GPIO_InitStruct.Mode = LL_GPIO_MODE_INPUT;
  GPIO_InitStruct.Pull = LL_GPIO_PULL_NO;
  LL_GPIO_Init(GPIOC, &GPIO_InitStruct);

  /**/
  GPIO_InitStruct.Pin = DI_ENABLE_1_Pin|DI_ENABLE_2_Pin|DI_ENABLE_3_Pin|DI_ENABLE_4_Pin;
  GPIO_InitStruct.Mode = LL_GPIO_MODE_OUTPUT;
  GPIO_InitStruct.Speed = LL_GPIO_SPEED_FREQ_LOW;
  GPIO_InitStruct.OutputType = LL_GPIO_OUTPUT_OPENDRAIN;
  GPIO_InitStruct.Pull = LL_GPIO_PULL_NO;
  LL_GPIO_Init(GPIOC, &GPIO_InitStruct);

  /**/
  GPIO_InitStruct.Pin = LD2_Pin;
  GPIO_InitStruct.Mode = LL_GPIO_MODE_OUTPUT;
  GPIO_InitStruct.Speed = LL_GPIO_SPEED_FREQ_LOW;
  GPIO_InitStruct.OutputType = LL_GPIO_OUTPUT_PUSHPULL;
  GPIO_InitStruct.Pull = LL_GPIO_PULL_NO;
  LL_GPIO_Init(LD2_GPIO_Port, &GPIO_InitStruct);

  /**/
  GPIO_InitStruct.Pin = Brake_Light_Pin;
  GPIO_InitStruct.Mode = LL_GPIO_MODE_OUTPUT;
  GPIO_InitStruct.Speed = LL_GPIO_SPEED_FREQ_LOW;
  GPIO_InitStruct.OutputType = LL_GPIO_OUTPUT_PUSHPULL;
  GPIO_InitStruct.Pull = LL_GPIO_PULL_NO;
  LL_GPIO_Init(Brake_Light_GPIO_Port, &GPIO_InitStruct);

  /**/
  GPIO_InitStruct.Pin = IMD_OK_Pin|MCU_INTLCK_Pin;
  GPIO_InitStruct.Mode = LL_GPIO_MODE_OUTPUT;
  GPIO_InitStruct.Speed = LL_GPIO_SPEED_FREQ_LOW;
  GPIO_InitStruct.OutputType = LL_GPIO_OUTPUT_PUSHPULL;
  GPIO_InitStruct.Pull = LL_GPIO_PULL_NO;
  LL_GPIO_Init(GPIOC, &GPIO_InitStruct);

  /**/
  GPIO_InitStruct.Pin = AMS_OK_Pin;
  GPIO_InitStruct.Mode = LL_GPIO_MODE_OUTPUT;
  GPIO_InitStruct.Speed = LL_GPIO_SPEED_FREQ_LOW;
  GPIO_InitStruct.OutputType = LL_GPIO_OUTPUT_PUSHPULL;
  GPIO_InitStruct.Pull = LL_GPIO_PULL_NO;
  LL_GPIO_Init(AMS_OK_GPIO_Port, &GPIO_InitStruct);

  /**/
  GPIO_InitStruct.Pin = LL_GPIO_PIN_7;
  GPIO_InitStruct.Mode = LL_GPIO_MODE_ALTERNATE;
  GPIO_InitStruct.Speed = LL_GPIO_SPEED_FREQ_VERY_HIGH;
  GPIO_InitStruct.OutputType = LL_GPIO_OUTPUT_PUSHPULL;
  GPIO_InitStruct.Pull = LL_GPIO_PULL_NO;
  GPIO_InitStruct.Alternate = LL_GPIO_AF_7;
  LL_GPIO_Init(GPIOB, &GPIO_InitStruct);

}

void HAL_TIM_PeriodElapsedCallback(TIM_HandleTypeDef *htim)
{
  if (htim->Instance == TIM5)
  {
    HAL_IncTick();
  }
}

void Error_Handler(void)
{
  __disable_irq();
  while (1)
  {
  }
}
